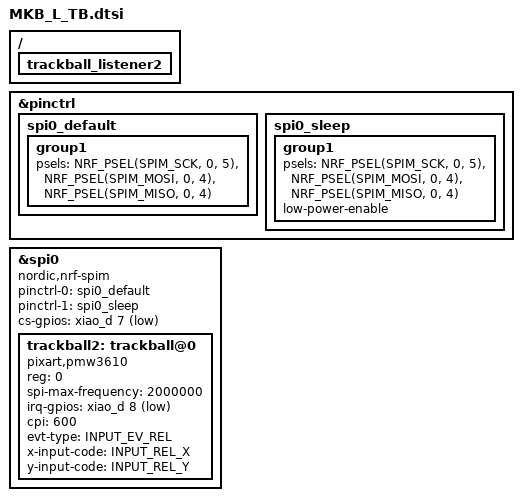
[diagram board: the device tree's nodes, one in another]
#include <dt-bindings/zmk/bt.h>
#include <input/processors.dtsi>
#include <dt-bindings/zmk/input_transform.h>
#include <zephyr/dt-bindings/input/input-event-codes.h>

&pinctrl {
    spi0_default: spi0_default {
        group1 {
            psels = <NRF_PSEL(SPIM_SCK, 0, 5)>,
                    <NRF_PSEL(SPIM_MOSI, 0, 4)>,
                    <NRF_PSEL(SPIM_MISO, 0, 4)>;
        };
    };

    spi0_sleep: spi0_sleep {
        group1 {
            psels = <NRF_PSEL(SPIM_SCK, 0, 5)>,
                    <NRF_PSEL(SPIM_MOSI, 0, 4)>,
                    <NRF_PSEL(SPIM_MISO, 0, 4)>;
            low-power-enable;
        };
    };
};

/ {
    trackball_listener2 {
        status = "okay";
    };
};

&spi0 {
    status = "okay";
    compatible = "nordic,nrf-spim";
    pinctrl-0 = <&spi0_default>;
    pinctrl-1 = <&spi0_sleep>;
    pinctrl-names = "default", "sleep";
    cs-gpios = <&xiao_d 7 GPIO_ACTIVE_LOW>;

    trackball2: trackball@0 {
        status = "okay";
        compatible = "pixart,pmw3610";
        reg = <0>;
        spi-max-frequency = <2000000>;
        irq-gpios = <&xiao_d 8 (GPIO_ACTIVE_LOW | GPIO_PULL_UP)>;
        cpi = <600>;
        evt-type = <INPUT_EV_REL>;
        x-input-code = <INPUT_REL_X>;
        y-input-code = <INPUT_REL_Y>;
    };
};
